# nrf51 register map
Vendor: Nordic Semiconductor; Series: nrf51; File version: 522
CPU: CM0 r3p1, little endian, no MPU, no FPU, 2 interrupt priority bits
Registers are 32-bit, read-write, reset 0x0 unless marked. A register's access mark holds for its fields unless they carry their own. Offsets are from the block's base; [hi:lo] are bit positions; {n}, {i} and the like mark numbered series.

## RTC0 — Real time counter 0.
Base 0x4000B000
Same registers: RTC1 0x40011000
0x00 TASKS_START wo — Start RTC Counter.
0x04 TASKS_STOP wo — Stop RTC Counter.
0x08 TASKS_CLEAR wo — Clear RTC Counter.
0x0C TASKS_TRIGOVRFLW wo — Set COUNTER to 0xFFFFFFF0.
0x100 EVENTS_TICK — Event on COUNTER increment.
0x104 EVENTS_OVRFLW — Event on COUNTER overflow.
{0x140+4i} EVENTS_COMPARE[{i}] (i=0..3) — Compare event on CC[n] match.
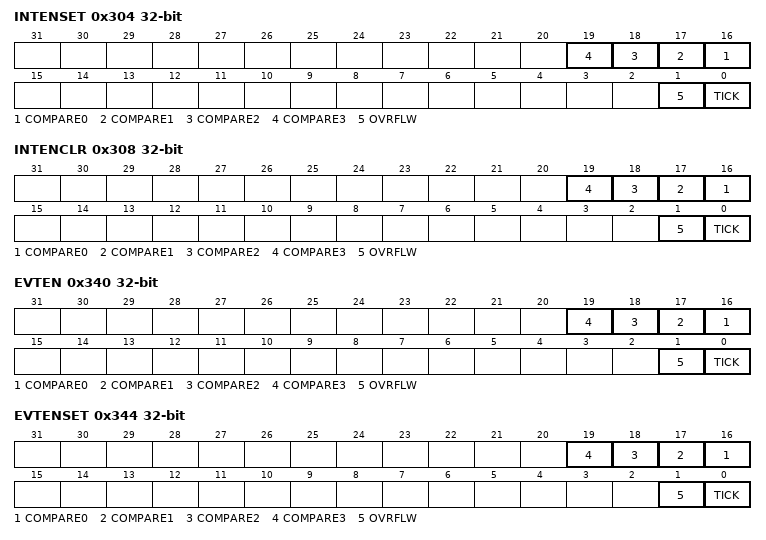
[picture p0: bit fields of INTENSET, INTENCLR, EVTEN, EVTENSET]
0x304 INTENSET — Interrupt enable set register.
  [all] fields
    on read: 0=Disabled (Interrupt disabled.); 1=Enabled (Interrupt enabled.) | on write: 1=Set (Enable interrupt on write.)
  [n+16] COMPARE{n} (n=0..3) — Enable interrupt on COMPARE[{n}] event.
  [1] OVRFLW — Enable interrupt on OVRFLW event.
  [0] TICK — Enable interrupt on TICK event.
0x308 INTENCLR — Interrupt enable clear register.
  [all] fields
    on read: 0=Disabled (Interrupt disabled.); 1=Enabled (Interrupt enabled.) | on write: 1=Clear (Disable interrupt on write.)
  [n+16] COMPARE{n} (n=0..3) — Disable interrupt on COMPARE[{n}] event.
  [1] OVRFLW — Disable interrupt on OVRFLW event.
  [0] TICK — Disable interrupt on TICK event.
0x340 EVTEN — Configures event enable routing to PPI for each RTC event.
  [all] fields
    0=Disabled (Event disabled.); 1=Enabled (Event enabled.)
  [n+16] COMPARE{n} (n=0..3) — COMPARE[{n}] event enable.
  [1] OVRFLW — OVRFLW event enable.
  [0] TICK — TICK event enable.
0x344 EVTENSET — Enable events routing to PPI. The reading of this register gives the value of EVTEN.
  [all] fields
    on read: 0=Disabled (Event disabled.); 1=Enabled (Event enabled.) | on write: 1=Set (Enable event on write.)
  [n+16] COMPARE{n} (n=0..3) — Enable routing to PPI of COMPARE[{n}] event.
  [1] OVRFLW — Enable routing to PPI of OVRFLW event.
  [0] TICK — Enable routing to PPI of TICK event.
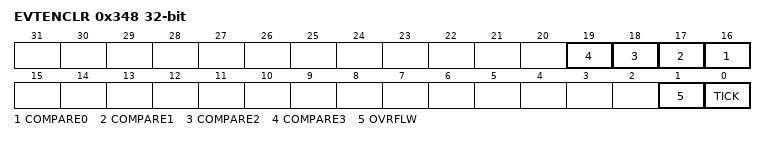
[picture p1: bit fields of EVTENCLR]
0x348 EVTENCLR — Disable events routing to PPI. The reading of this register gives the value of EVTEN.
  [all] fields
    on read: 0=Disabled (Event disabled.); 1=Enabled (Event enabled.) | on write: 1=Clear (Disable event on write.)
  [n+16] COMPARE{n} (n=0..3) — Disable routing to PPI of COMPARE[{n}] event.
  [1] OVRFLW — Disable routing to PPI of OVRFLW event.
  [0] TICK — Disable routing to PPI of TICK event.
0x504 COUNTER ro — Current COUNTER value.
  [23:0] COUNTER — Counter value.
0x508 PRESCALER — 12-bit prescaler for COUNTER frequency (32768/(PRESCALER+1)). Must be written when RTC is stopped.
  [11:0] PRESCALER — RTC PRESCALER value.
{0x540+4i} CC[{i}] (i=0..3) — Capture/compare registers.
  [23:0] COMPARE — Compare value.
0xFFC POWER — Peripheral power control.
  [0] POWER
    0=Disabled (Module power disabled.); 1=Enabled (Module power enabled.)

## TEMP — Temperature Sensor.
Base 0x4000C000
0x00 TASKS_START wo — Start temperature measurement.
0x04 TASKS_STOP wo — Stop temperature measurement.
0x100 EVENTS_DATARDY — Temperature measurement complete, data ready event.
0x304 INTENSET — Interrupt enable set register.
  [0] DATARDY — Enable interrupt on DATARDY event.
    on read: 0=Disabled (Interrupt disabled.); 1=Enabled (Interrupt enabled.) | on write: 1=Set (Enable interrupt on write.)
0x308 INTENCLR — Interrupt enable clear register.
  [0] DATARDY — Disable interrupt on DATARDY event.
    on read: 0=Disabled (Interrupt disabled.); 1=Enabled (Interrupt enabled.) | on write: 1=Clear (Disable interrupt on write.)
0x508 TEMP ro — Die temperature in degC, 2's complement format, 0.25 degC pecision.
0xFFC POWER — Peripheral power control.
  [0] POWER
    0=Disabled (Module power disabled.); 1=Enabled (Module power enabled.)
